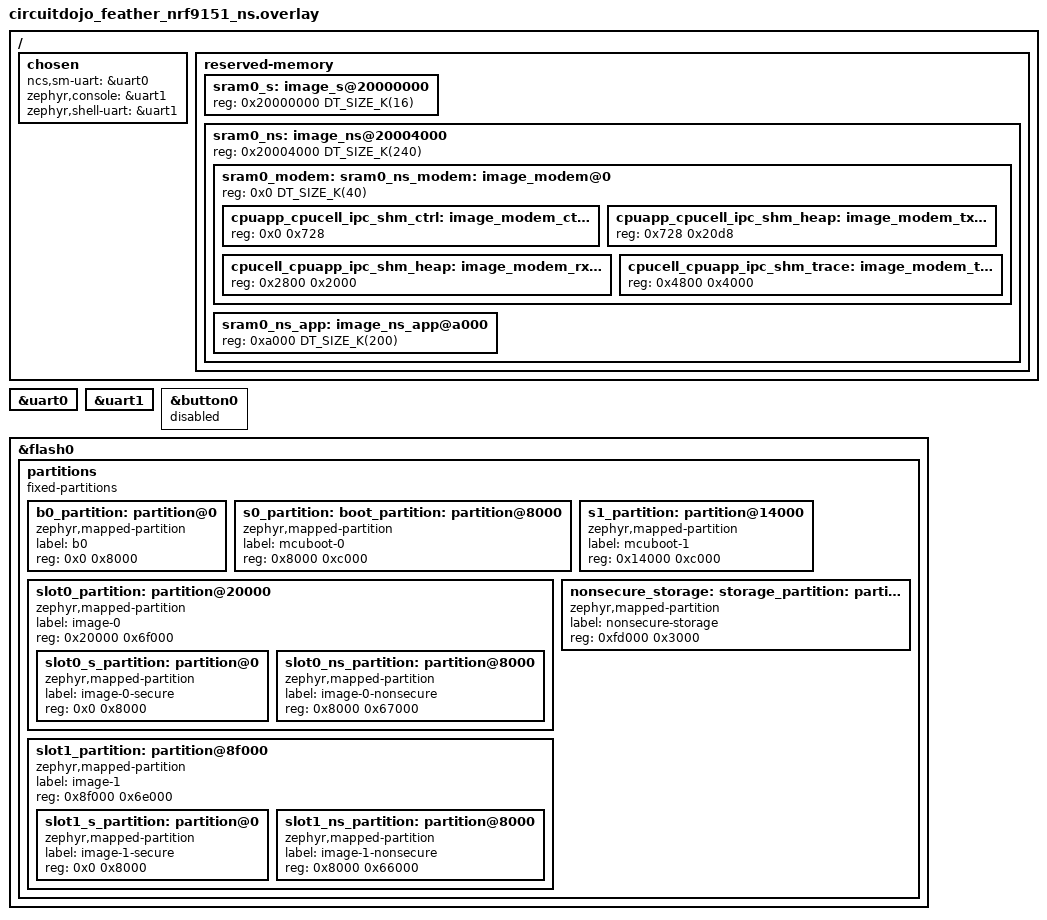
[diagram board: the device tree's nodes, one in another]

/ {
	chosen {
		ncs,sm-uart = &uart0;
		/*
		 * Keep the console/shell off uart0: uart0 is the AT host UART and is
		 * brought up with async RX, so sm_log_init() cannot PM-suspend it
		 * (uarte_pm_suspend() returns -EAGAIN while RX is enabled), which is
		 * reported as "INIT ERROR". Move the console to uart1, the modem-trace
		 * UART, matching the nRF9151 DK / Thingy91x layout. App logs are off by
		 * default and enabled at runtime with AT#XLOG.
		 */
		zephyr,console = &uart1;
		zephyr,shell-uart = &uart1;
	};
};

&uart0 {
	status = "okay";
};

&uart1 {
	status = "okay";
};

&button0 {
	status = "disabled";
};

/*
 * Flash partition layout for the nRF9151 Feather with B0 and updatable MCUboot.
 *
 * 0x0000_0000  b0 (NSIB)                    ( 32 kB)
 * 0x0000_8000  s0 (MCUboot image, slot 0)   ( 48 kB)
 * 0x0001_4000  s1 (MCUboot image, slot 1)   ( 48 kB)
 * 0x0002_0000  slot0 (primary app)          (444 kB)
 *   0x0002_0000  TF-M secure                ( 32 kB)
 *   0x0002_8000  Application (non-secure)   (412 kB)
 * 0x0008_f000  slot1 (secondary app)        (440 kB)
 * 0x000f_d000  Non-secure storage           ( 12 kB)
 */

/delete-node/ &boot_partition;
/delete-node/ &slot0_partition;
/delete-node/ &slot1_partition;
/delete-node/ &tfm_ps_partition;
/delete-node/ &tfm_its_partition;
/delete-node/ &tfm_otp_partition;
/delete-node/ &storage_partition;

&flash0 {
	partitions {
		compatible = "fixed-partitions";
		#address-cells = <1>;
		#size-cells = <1>;

		b0_partition: partition@0 {
			compatible = "zephyr,mapped-partition";
			label = "b0";
			reg = <0x0 0x8000>;
		};

		s0_partition: boot_partition: partition@8000 {
			compatible = "zephyr,mapped-partition";
			label = "mcuboot-0";
			reg = <0x8000 0xc000>;
		};

		s1_partition: partition@14000 {
			compatible = "zephyr,mapped-partition";
			label = "mcuboot-1";
			reg = <0x14000 0xc000>;
		};

		slot0_partition: partition@20000 {
			compatible = "zephyr,mapped-partition";
			label = "image-0";
			reg = <0x20000 0x6f000>;
			ranges = <0x0 0x20000 0x6f000>;
			#address-cells = <1>;
			#size-cells = <1>;

			slot0_s_partition: partition@0 {
				compatible = "zephyr,mapped-partition";
				label = "image-0-secure";
				reg = <0x0 0x8000>;
			};

			slot0_ns_partition: partition@8000 {
				compatible = "zephyr,mapped-partition";
				label = "image-0-nonsecure";
				reg = <0x8000 0x67000>;
			};
		};

		slot1_partition: partition@8f000 {
			compatible = "zephyr,mapped-partition";
			label = "image-1";
			reg = <0x8f000 0x6e000>;
			ranges = <0x0 0x8f000 0x6e000>;
			#address-cells = <1>;
			#size-cells = <1>;

			slot1_s_partition: partition@0 {
				compatible = "zephyr,mapped-partition";
				label = "image-1-secure";
				reg = <0x0 0x8000>;
			};

			slot1_ns_partition: partition@8000 {
				compatible = "zephyr,mapped-partition";
				label = "image-1-nonsecure";
				reg = <0x8000 0x66000>;
			};
		};

		nonsecure_storage: storage_partition: partition@fd000 {
			compatible = "zephyr,mapped-partition";
			label = "nonsecure-storage";
			reg = <0xfd000 0x3000>;
		};
	};
};

/*
 * Application SRAM layout. Keep the modem trace IPC area from the Feather board,
 * but reduce secure RAM so the non-secure serial modem application has room.
 */

/delete-node/ &sram0_s;
/delete-node/ &sram0_ns;

/ {
	reserved-memory {
		sram0_s: image_s@20000000 {
			reg = <0x20000000 DT_SIZE_K(16)>;
		};

		sram0_ns: image_ns@20004000 {
			reg = <0x20004000 DT_SIZE_K(240)>;
			#address-cells = <1>;
			#size-cells = <1>;
			ranges = <0x0 0x20004000 DT_SIZE_K(240)>;

			sram0_modem: sram0_ns_modem: image_modem@0 {
				reg = <0x0 DT_SIZE_K(40)>;
				#address-cells = <1>;
				#size-cells = <1>;
				ranges = <0x0 0x0 DT_SIZE_K(40)>;

				cpuapp_cpucell_ipc_shm_ctrl: image_modem_ctrl@0 {
					reg = <0x0 0x728>;
				};

				cpuapp_cpucell_ipc_shm_heap: image_modem_tx@728 {
					reg = <0x728 0x20d8>;
				};

				cpucell_cpuapp_ipc_shm_heap: image_modem_rx@2800 {
					reg = <0x2800 0x2000>;
				};

				cpucell_cpuapp_ipc_shm_trace: image_modem_trace@4800 {
					reg = <0x4800 0x4000>;
				};
			};

			sram0_ns_app: image_ns_app@a000 {
				reg = <0xa000 DT_SIZE_K(200)>;
			};
		};
	};
};
